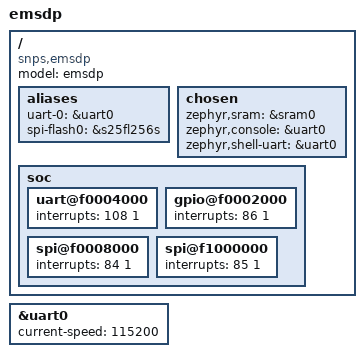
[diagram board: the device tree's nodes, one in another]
/*
 * Copyright (c) 2019, Synopsys, Inc. All rights reserved.
 *
 * SPDX-License-Identifier: Apache-2.0
 */

/dts-v1/;

#include <synopsys/emsdp-sec.dtsi>
#include "board.dtsi"

/ {
	model = "emsdp";
	compatible = "snps,emsdp", "snps,emsdp";

	aliases {
		uart-0 = &uart0;
		spi-flash0 = &s25fl256s;
	};

	chosen {
		zephyr,sram = &sram0;
		zephyr,console = &uart0;
		zephyr,shell-uart = &uart0;
	};
};

&uart0 {
	status = "okay";
	current-speed = <115200>;
};

/ {
	soc {

		uart@f0004000 {
			interrupts = <108 1>;
		};

		gpio@f0002000 {
			interrupts = <86 1>;
		};

		/* IRQ line in em7d_esp is different to others */
		spi@f0008000 {
			interrupts = <84 1>;
		};

		spi@f1000000 {
			interrupts = <85 1>;
		};
	};
};
